# STM32F303VCY7 register map
File version: 1.0
Registers are 32-bit, access not given, reset 0x0 unless marked. A register's access mark holds for its fields unless they carry their own. Offsets are from the block's base; [hi:lo] are bit positions; {n}, {i} and the like mark numbered series; 'fields as' and 'values as' point back to an identical list.

## DMA1
Base 0x40020000
Same registers: DMA2 0x40020400
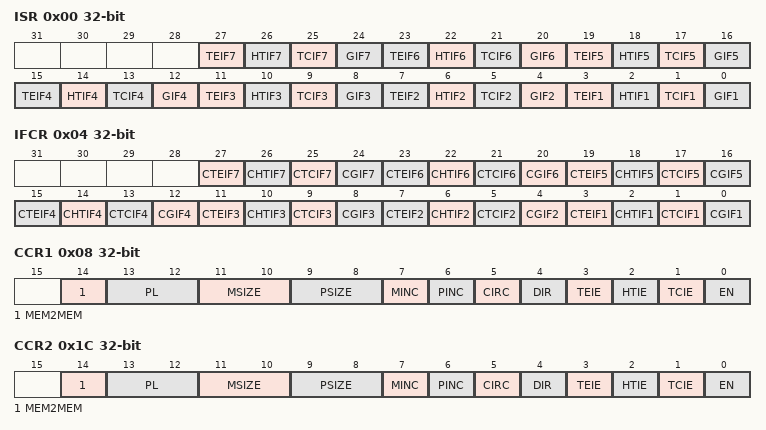
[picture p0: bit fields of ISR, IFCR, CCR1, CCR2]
0x00 ISR
  [4n-1] TEIF{n} (n=1..7), [4n-2] HTIF{n} (n=1..7), [4n-3] TCIF{n} (n=1..7), [4n-4] GIF{n} (n=1..7)
0x04 IFCR
  [4n-1] CTEIF{n} (n=1..7), [4n-2] CHTIF{n} (n=1..7), [4n-3] CTCIF{n} (n=1..7), [4n-4] CGIF{n} (n=1..7)
0x08 CCR1
  [14] MEM2MEM, [13:12] PL, [11:10] MSIZE, [9:8] PSIZE, [7] MINC, [6] PINC, [5] CIRC, [4] DIR, [3] TEIE, [2] HTIE, [1] TCIE, [0] EN
0x0C CNDTR1
  [15:0] NDT
0x10 CPAR1
  [31:0] PA
{0x0+0x14*i} CMAR{i} (i=1..7)
  [31:0] MA
0x1C CCR2
  fields as CCR1
0x20 CNDTR2
  [15:0] NDT
0x24 CPAR2
  [31:0] PA
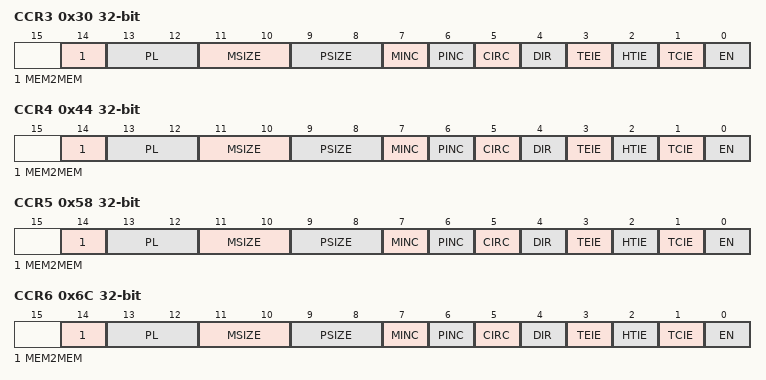
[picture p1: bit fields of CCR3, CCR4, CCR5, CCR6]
0x30 CCR3
  fields as CCR1
0x34 CNDTR3
  [15:0] NDT
0x38 CPAR3
  [31:0] PA
0x44 CCR4
  fields as CCR1
0x48 CNDTR4
  [15:0] NDT
0x4C CPAR4
  [31:0] PA
0x58 CCR5
  fields as CCR1
0x5C CNDTR5
  [15:0] NDT
0x60 CPAR5
  [31:0] PA
0x6C CCR6
  fields as CCR1
0x70 CNDTR6
  [15:0] NDT
0x74 CPAR6
  [31:0] PA
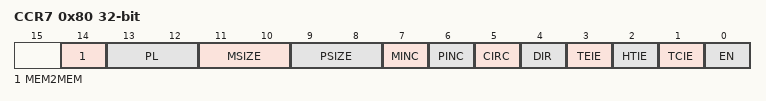
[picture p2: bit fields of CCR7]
0x80 CCR7
  fields as CCR1
0x84 CNDTR7
  [15:0] NDT
0x88 CPAR7
  [31:0] PA

## RCC
Base 0x40021000
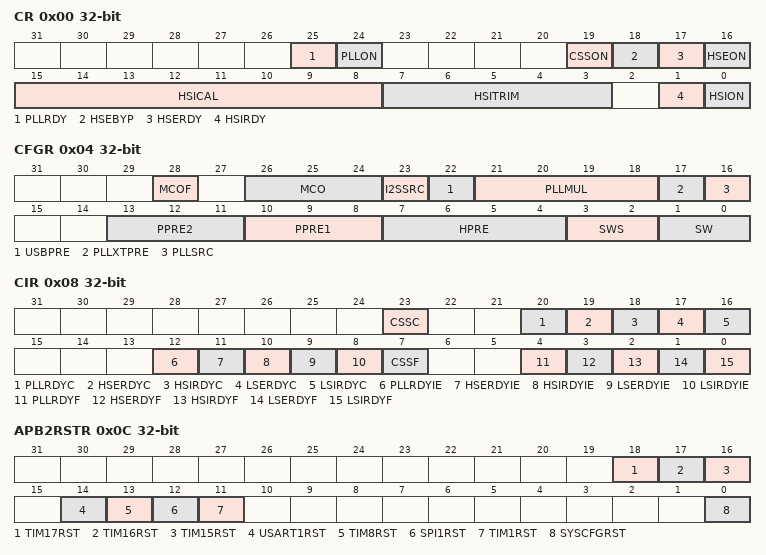
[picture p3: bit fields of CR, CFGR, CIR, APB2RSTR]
0x00 CR
  [25] PLLRDY, [24] PLLON, [19] CSSON, [18] HSEBYP, [17] HSERDY, [16] HSEON, [15:8] HSICAL, [7:3] HSITRIM, [1] HSIRDY, [0] HSION
0x04 CFGR
  [28] MCOF, [26:24] MCO, [23] I2SSRC, [22] USBPRE, [21:18] PLLMUL, [17] PLLXTPRE, [16] PLLSRC, [13:11] PPRE2, [10:8] PPRE1, [7:4] HPRE, [3:2] SWS, [1:0] SW
0x08 CIR
  [23] CSSC, [20] PLLRDYC, [19] HSERDYC, [18] HSIRDYC, [17] LSERDYC, [16] LSIRDYC, [12] PLLRDYIE, [11] HSERDYIE, [10] HSIRDYIE, [9] LSERDYIE, [8] LSIRDYIE, [7] CSSF, [4] PLLRDYF, [3] HSERDYF, [2] HSIRDYF, [1] LSERDYF, [0] LSIRDYF
0x0C APB2RSTR
  [18] TIM17RST, [17] TIM16RST, [16] TIM15RST, [14] USART1RST, [13] TIM8RST, [12] SPI1RST, [11] TIM1RST, [0] SYSCFGRST
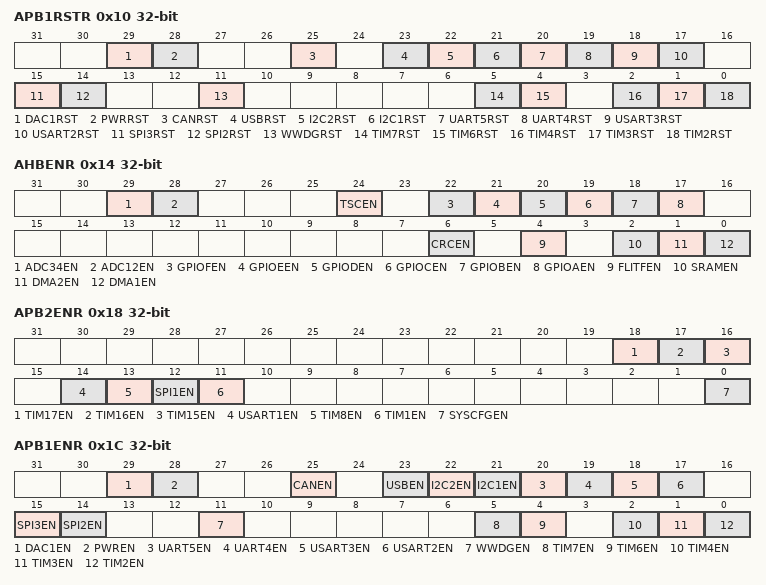
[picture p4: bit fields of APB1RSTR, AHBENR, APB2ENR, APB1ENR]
0x10 APB1RSTR
  [29] DAC1RST, [28] PWRRST, [25] CANRST, [23] USBRST, [22] I2C2RST, [21] I2C1RST, [20] UART5RST, [19] UART4RST, [18] USART3RST, [17] USART2RST, [15] SPI3RST, [14] SPI2RST, [11] WWDGRST, [5] TIM7RST, [4] TIM6RST, [2] TIM4RST, [1] TIM3RST, [0] TIM2RST
0x14 AHBENR
  [29] ADC34EN, [28] ADC12EN, [24] TSCEN, [22] GPIOFEN, [21] GPIOEEN, [20] GPIODEN, [19] GPIOCEN, [18] GPIOBEN, [17] GPIOAEN, [6] CRCEN, [4] FLITFEN, [2] SRAMEN, [1] DMA2EN, [0] DMA1EN
0x18 APB2ENR
  [18] TIM17EN, [17] TIM16EN, [16] TIM15EN, [14] USART1EN, [13] TIM8EN, [12] SPI1EN, [11] TIM1EN, [0] SYSCFGEN
0x1C APB1ENR
  [29] DAC1EN, [28] PWREN, [25] CANEN, [23] USBEN, [22] I2C2EN, [21] I2C1EN, [20] UART5EN, [19] UART4EN, [18] USART3EN, [17] USART2EN, [15] SPI3EN, [14] SPI2EN, [11] WWDGEN, [5] TIM7EN, [4] TIM6EN, [2] TIM4EN, [1] TIM3EN, [0] TIM2EN
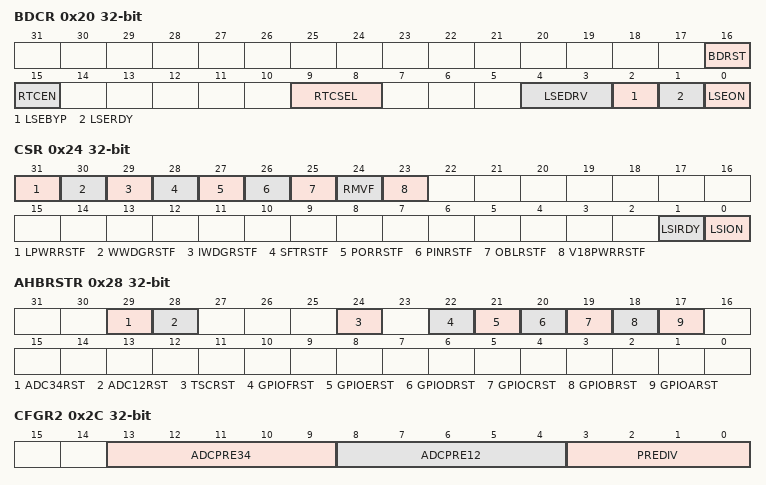
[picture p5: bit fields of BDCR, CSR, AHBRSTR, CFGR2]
0x20 BDCR
  [16] BDRST, [15] RTCEN, [9:8] RTCSEL, [4:3] LSEDRV, [2] LSEBYP, [1] LSERDY, [0] LSEON
0x24 CSR
  [31] LPWRRSTF, [30] WWDGRSTF, [29] IWDGRSTF, [28] SFTRSTF, [27] PORRSTF, [26] PINRSTF, [25] OBLRSTF, [24] RMVF, [23] V18PWRRSTF, [1] LSIRDY, [0] LSION
0x28 AHBRSTR
  [29] ADC34RST, [28] ADC12RST, [24] TSCRST, [22] GPIOFRST, [21] GPIOERST, [20] GPIODRST, [19] GPIOCRST, [18] GPIOBRST, [17] GPIOARST
0x2C CFGR2
  [13:9] ADCPRE34, [8:4] ADCPRE12, [3:0] PREDIV
0x30 CFGR3
  [23:22] UART5SW, [21:20] UART4SW, [19:18] USART3SW, [17:16] USART2SW, [9] TIM8SW_PLL, [9:8] TIMSW, [5] I2C2SW_SYSCLK, [5:4] I2CSW, [1:0] USART1SW

## FLASH
Base 0x40022000
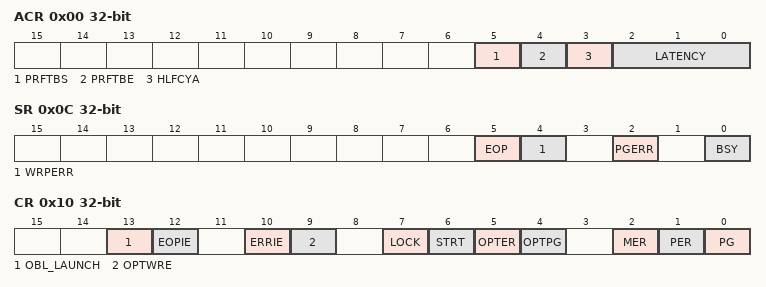
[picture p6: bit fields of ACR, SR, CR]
0x00 ACR
  [5] PRFTBS, [4] PRFTBE, [3] HLFCYA, [2:0] LATENCY
0x04 KEYR
  [31:0] FKEYR
0x08 OPTKEYR
0x0C SR
  [5] EOP, [4] WRPERR, [2] PGERR, [0] BSY
0x10 CR
  [13] OBL_LAUNCH, [12] EOPIE, [10] ERRIE, [9] OPTWRE, [7] LOCK, [6] STRT, [5] OPTER, [4] OPTPG, [2] MER, [1] PER, [0] PG
0x14 AR
  [31:0] FAR
0x1C OBR
  [31:24] DATA1, [23:16] DATA0, [14] SRAM_PE, [13] VDDA_MONITOR, [12] nBOOT1, [10] nRST_STDBY, [9] nRST_STOP, [14:8] USER, [2:1] RDPRT, [0] OPTERR
0x20 WRPR
  [31:0] WRP

## CRC
Base 0x40023000
0x00 DR
0x04 IDR 8-bit
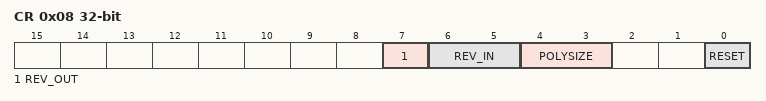
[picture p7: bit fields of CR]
0x08 CR
  [7] REV_OUT, [6:5] REV_IN, [4:3] POLYSIZE, [0] RESET
0x10 INIT
0x14 POL
